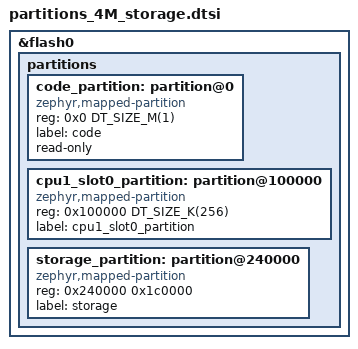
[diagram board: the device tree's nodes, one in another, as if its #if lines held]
/*
 * Copyright (c) 2025 Beechwoods Software, Inc.
 *
 * SPDX-License-Identifier: Apache-2.0
 */

&flash0 {
	partitions {
		ranges;
		#address-cells = <0x1>;
		#size-cells = <0x1>;

		code_partition: partition@0 {
			compatible = "zephyr,mapped-partition";
			reg = <0x0 DT_SIZE_M(1)>;
			label = "code";
			read-only;
		};

#ifdef WITH_CPU1_PARTITIONS
		cpu1_slot0_partition: partition@100000 {
			compatible = "zephyr,mapped-partition";
			reg = <0x100000 DT_SIZE_K(256)>;
			label = "cpu1_slot0_partition";
		};

		storage_partition: partition@240000 {
			compatible = "zephyr,mapped-partition";
			reg = <0x240000 0x1c0000>;
			label = "storage";
		};
#else
		storage_partition: partition@100000 {
			compatible = "zephyr,mapped-partition";
			reg = <0x100000 DT_SIZE_M(3)>;
			label = "storage";
		};
#endif
	};
};
